# core_model: IP-XACT component
VLNV IcronTechnologies:IcronTechnologies:core_model:1.0

## Parameters
addr_width = 8
bus_width = 32

## Bus interfaces (logical=physical port)
default_map: slave AGNISYS:AGNISYS:APB:1.0, memory map coremap
  pclk=pclk, presetn=presetn, psel=psel, penable=penable, pwrite=pwrite, pprot=pprot, pstrb=pstrb, pwdata=pwdata, paddr=paddr, pready=pready, prdata=prdata, pslverr=pslverr

## Ports
in pclk
in presetn
in psel
in penable
in pwrite
in pprot[2:0]
in pstrb[(bus_width div 8 )-1:0]
in pwdata[bus_width -1:0]
in paddr[addr_width -1:0]
out pready
out prdata[bus_width -1:0]
out pslverr
out mca_core_regscontrol0_enb
out mca_core_regscontrol0_dp_rx_en_r
out mca_core_regscontrol0_dp_tx_en_r
in mca_core_regsstatus0_dp_rx_ready_in
in mca_core_regsstatus0_dp_rx_ready_in_enb
in mca_core_regsstatus0_dp_tx_ready_in
in mca_core_regsstatus0_dp_tx_ready_in_enb
out mca_core_regslink_control0_ltssm_pkt_mngt_pol_enb
out mca_core_regslink_control0_ltssm_pkt_mngt_pol_rx_idl_en_min_r[3:0]
out mca_core_regslink_control0_ltssm_pkt_mngt_pol_tx_idl_min_r[3:0]
out mca_core_regslink_control0_ltssm_pkt_mngt_pol_rx_idl_min_r[3:0]
out mca_core_regslink_control0_ltssm_pkt_mngt_pol_rx_ts1_en_min_r[3:0]
out mca_core_regslink_control0_ltssm_pkt_mngt_pol_tx_ts1_min_r[3:0]
out mca_core_regslink_control0_ltssm_pkt_mngt_pol_rx_ts1_min_r[3:0]
out mca_core_regslink_control0_ltssm_pkt_mngt_rec_enb
out mca_core_regslink_control0_ltssm_pkt_mngt_rec_rx_idl_en_max_lmt_r[3:0]
out mca_core_regslink_control0_ltssm_pkt_mngt_rec_tx_idl_max_lmt_r[3:0]
out mca_core_regslink_control0_ltssm_pkt_mngt_rec_rx_idl_max_lmt_r[3:0]
out mca_core_regslink_control0_ltssm_pkt_mngt_rec_rx_ts2_en_max_lmt_r[3:0]
out mca_core_regslink_control0_ltssm_pkt_mngt_rec_tx_ts2_max_lmt_r[3:0]
out mca_core_regslink_control0_ltssm_pkt_mngt_rec_rx_ts2_max_lmt_r[3:0]
out mca_core_regslink_control0_ltssm_pol_tmr_act_rpt_enb
out mca_core_regslink_control0_ltssm_pol_tmr_act_rpt_lmt_r[31:0]
out mca_core_regslink_control0_ltssm_pol_tmr_idle_rpt_enb
out mca_core_regslink_control0_ltssm_pol_tmr_idle_rpt_lmt_r[31:0]
out mca_core_regslink_control0_ltssm_pol_tmr_idle_enb
out mca_core_regslink_control0_ltssm_pol_tmr_idle_lmt_r[31:0]
out mca_core_regslink_control0_ltssm_rec_tmr_act_rpt_enb
out mca_core_regslink_control0_ltssm_rec_tmr_act_rpt_lmt_r[31:0]
out mca_core_regslink_control0_ltssm_rec_tmr_idle_rpt_enb
out mca_core_regslink_control0_ltssm_rec_tmr_idle_rpt_lmt_r[31:0]
out mca_core_regslink_control0_ltssm_rec_tmr_idle_enb
out mca_core_regslink_control0_ltssm_rec_tmr_idle_lmt_r[31:0]
out mca_core_regslink_control0_ltssm_u0_tmr_u0ltimeout_enb
out mca_core_regslink_control0_ltssm_u0_tmr_u0ltimeout_lmt_r[31:0]
out mca_core_regslink_control0_ltssm_u0_tmr_pnd_enb
out mca_core_regslink_control0_ltssm_u0_tmr_pnd_lmt_r[31:0]
out mca_core_regslink_control0_ltssm_u0_tmr_crd_enb
out mca_core_regslink_control0_ltssm_u0_tmr_crd_lmt_r[31:0]
out mca_core_regslink_control0_ltssm_u0_tmr_u0rectimeout_enb
out mca_core_regslink_control0_ltssm_u0_tmr_u0rectimeout_lmt_r[31:0]
out mca_core_regslink_control0_test_latency_enb
out mca_core_regslink_control0_test_latency_lmt_r[31:0]
out mca_core_regstx_control0_dp_enb
out mca_core_regstx_control0_dp_stats_chid_en_r[15:0]
out mca_core_regstx_control0_dp_bw_pkt_type_r[3:0]
out mca_core_regstx_control0_bw_sample_timer_enb
out mca_core_regstx_control0_bw_sample_timer_cnt_r[15:0]
out mca_core_regstx_stats0_rd2clr_config_rd_valid_out
out mca_core_regstx_stats0_rd2clr_config_wr_valid_out
out mca_core_regstx_stats0_pfifo_rd_valid_out
out mca_core_regstx_stats0_nfifo_rd_valid_out
out mca_core_regstx_stats0_cmd_fifo_dcount_rd_valid_out
out mca_core_regstx_stats0_data_pkt_nrtry_rd_valid_out
out mca_core_regstx_stats0_data_pkt_rtry_rd_valid_out
out mca_core_regstx_stats0_idle_rd_valid_out
out mca_core_regstx_stats0_ts2_rd_valid_out
out mca_core_regstx_stats0_ts1_rd_valid_out
out mca_core_regstx_stats0_lbad_rd_valid_out
out mca_core_regstx_stats0_lrtry_rd_valid_out
out mca_core_regstx_stats0_lcrd_rd_valid_out
out mca_core_regstx_stats0_lgood_rd_valid_out
out mca_core_regstx_stats0_plu_rd_valid_out
out mca_core_regstx_stats0_bandwidth_rd_valid_out
out mca_core_regsrx_control0_dp_enb
out mca_core_regsrx_control0_dp_stats_chid_en_r[15:0]
out mca_core_regsrx_control0_rx_cmd_fifo_flc_enb
out mca_core_regsrx_control0_rx_cmd_fifo_flc_hi_r[15:0]
out mca_core_regsrx_control0_rx_cmd_fifo_flc_lo_r[15:0]
out mca_core_regsrx_stats0_rd2clr_config_rd_valid_out
out mca_core_regsrx_stats0_rd2clr_config_wr_valid_out
out mca_core_regsrx_stats0_cmd_fifo_dcount_rd_valid_out
out mca_core_regsrx_stats0_data_pkt_nrtry_rd_valid_out
out mca_core_regsrx_stats0_data_pkt_rtry_rd_valid_out
out mca_core_regsrx_stats0_idle_rd_valid_out
out mca_core_regsrx_stats0_ts2_rd_valid_out
out mca_core_regsrx_stats0_ts1_rd_valid_out
out mca_core_regsrx_stats0_lbad_rd_valid_out
out mca_core_regsrx_stats0_lrtry_rd_valid_out
out mca_core_regsrx_stats0_lcrd_rd_valid_out
out mca_core_regsrx_stats0_lgood_rd_valid_out
out mca_core_regsrx_stats0_plu_rd_valid_out
out mca_core_regsrx_stats0_rx_cmd_fifo_flc_rd_valid_out

## Address spaces and blocks
coremap.core: base 0x000, range 0x100, width 32

## Registers
Registers are 32-bit, read-only, reset 0x0 unless marked. A register's access mark holds for its fields unless they carry their own. Offsets are from the block's base; lines under a group give offsets from that group; [hi:lo] are bit positions; {n}, {i} and the like mark numbered series; 'fields as' and 'values as' point back to an identical list; <NAME> marks a mode.

## coremap.core — MCA Channel register control
Base 0x00000000
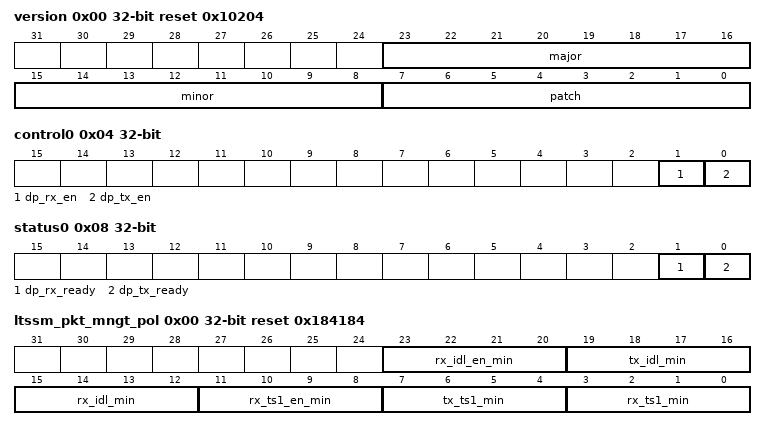
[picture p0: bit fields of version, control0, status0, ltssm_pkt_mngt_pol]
0x00 version reset 0x10204
  [23:16] major — Major version
  [15:8] minor — Minor version
  [7:0] patch — Patch version
0x04 control0 rw
  [1] dp_rx_en — Enables the datapath to receive packets
  [0] dp_tx_en — Enables the datapath to transmit packets
0x08 status0
  [1] dp_rx_ready — Indicates the datapath is ready for transmission
  [0] dp_tx_ready — Indicates the datapath is ready for reception
0x0C link group — This register group contains channel based link management controls and status information.
  0x00 control0 group — This register group contains channel based link management controls and status information.
    0x00 ltssm_pkt_mngt_pol rw reset 0x184184
      [23:20] rx_idl_en_min — Sets the minimum number of idle packets that must be received before starting to count the locally transmitted ts1.
      [19:16] tx_idl_min — Sets the minimum number of idle packets which must be transmitted before moving to the u0 state.
      [15:12] rx_idl_min — Sets minimum number of idle packets which must be received before moving to the u0 state.
      [11:8] rx_ts1_en_min — Sets the minimum number of ts1 packets that must be received before starting to count the locally transmitted ts1.
      [7:4] tx_ts1_min — Sets the minimum number of ts1 packets which must be transmitted before moving to the polling_idle state.
      [3:0] rx_ts1_min — Sets minimum number of ts1 packets which must be received before moving to the polling_idle state.
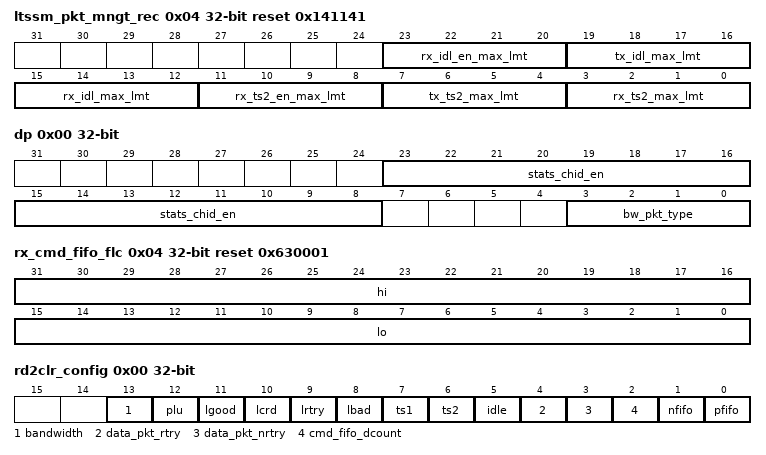
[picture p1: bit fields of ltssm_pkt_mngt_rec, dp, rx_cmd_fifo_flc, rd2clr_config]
    0x04 ltssm_pkt_mngt_rec rw reset 0x141141
      [23:20] rx_idl_en_max_lmt — Sets the minimum number of idle packets that must be received before starting to count the locally transmitted ts2.
      [19:16] tx_idl_max_lmt — Sets the minimum number of idle packets which must be transmitted before moving to the u0 state.
      [15:12] rx_idl_max_lmt — Sets minimum number of idle packets which must be received before moving to the u0 state.
      [11:8] rx_ts2_en_max_lmt — Sets the minimum number of ts2 packets that must be received before starting to count the locally transmitted ts1.
      [7:4] tx_ts2_max_lmt — Sets the minimum number of ts2 packets which must be transmitted before moving to the rec_idle state.
      [3:0] rx_ts2_max_lmt — Sets minimum number of ts2 packets which must be received before moving to the rec_idle state.
    0x08 ltssm_pol_tmr group
      0x00 act_rpt rw reset 0x1D5
        [31:0] lmt — This timer determine the rate at which ts1 packets are transmitted during polling_active (default approximately 3us)
      0x04 idle_rpt rw reset 0x1D5
        [31:0] lmt — This timer determine the rate at which idle packets are transmitted during polling_idle (default approximately 3us)
      0x08 idle rw reset 0x2625A
        [31:0] lmt — When in polling_ilde this timer determine how long to wait before re-starting the polling_active state. (default approximately 1ms)
    0x14 ltssm_rec_tmr group
      0x00 act_rpt rw reset 0x28
        [31:0] lmt — This timer determine the rate at which ts2 packets are transmitted during rec_active. (default approximately 0.25us)
      0x04 idle_rpt rw reset 0x28
        [31:0] lmt — This timer determine the rate at which idle packets are transmitted during rec_idle (default approximately 0.25us)
      0x08 idle rw reset 0x2625A
        [31:0] lmt — When in rec_ilde this timer determine how long to wait before declaring a recovery failure and declaring the port in-active. (default approximately 1ms)
    0x20 ltssm_u0_tmr group
      0x00 u0ltimeout rw reset 0x61B
        [31:0] lmt — When operating in U0 this timer defines the rate at which the system transmits keep alive packets (note these are only done in absence of transmitting data). (default approximately 10us)
      0x04 pnd rw reset 0x3D09
        [31:0] lmt — This timer sets the maximum time limit to wait for a response to be received from the remote port to a retry-able MCUP (default approximately 100us)
      0x08 crd rw reset 0x3D09
        [31:0] lmt — This sets the credit timeout.not implemented yet. (default approximately 100us)
      0x0C u0rectimeout rw reset 0x1312D
        [31:0] lmt — This timer sets the limit on how long to wait without seeing received traffic (link ups/data etc) from the remote end. (default approximately 500us)
    0x30 test group
      0x00 latency rw reset 0x3D09
        [31:0] lmt — This timer sets the rate at which the latency packet sequence is transmitted. Results are stored in the channel associated with the test. (default approximately 100us)
  0x34 status0 group
    0x00 cfg — General configuration settings for the link management logic
      [4:0] active_channels — Indicates how many channels are used in this instance of the MCA.
0x44 tx group
  0x00 control0 group
    0x00 dp rw
      [23:8] stats_chid_en — This field is represents the bit vector which selects the channel(s) which participate in the statistics collection. Bit X 1 - Include channel in statistics collection 0 - Exclude channel from statistics collection
      [3:0] bw_pkt_type — Defines the packet types which bandwidth measurements are taken measured at the egress of the MCA. 0 - all packet types 1 - lgood 2 - lcrd 3 - retriable mcup 4 - non-retriable mcup
    0x04 bw_sample_timer rw reset 0xFF — This register defines the sample period all bandwidth monitors use to calculate the average bandwidth. The clock reference is the core clock.
      [15:0] cnt — Defines the periodicity of the bandwidth sample clock
  0x08 stats0 group
    0x00 rd2clr_config rw — Configures if the stats register read by s/w clears the read register. A 1 in any bit configures the h/w to clear the corresponding stats register after a s/w read of that stats register.
      [13] bandwidth, [12] plu, [11] lgood, [10] lcrd, [9] lrtry, [8] lbad, [7] ts1, [6] ts2, [5] idle, [4] data_pkt_rtry, [3] data_pkt_nrtry, [2] cmd_fifo_dcount, [1] nfifo, [0] pfifo
    0x04 pfifo — Packet FIFO level. This is fixed at 16 elements (16 * 8= 128 bytes)
      [3:0] cnt
    0x08 nfifo — Notification FIFO level. This represents the number of MCUPS in the egress FIFO
      [3:0] cnt
    0x0C cmd_fifo_dcount — This is the common TX Command FIFO level.All channels send link commands through this FIFO
      [15:0] cnt
    0x10 data_pkt_nrtry — This represents the number of non-retriable data-packets are being sent
      [31:0] cnt
    0x14 data_pkt_rtry — This is the number of retriable packets which have been transmitted
      [31:0] cnt
    0x18 idle — Number if idle packets transmitted. These should be relatively low so this counter is small.
      [7:0] cnt
    0x1C ts2 — Number if ts2 packets transmitted. These should be relatively low so this counter is small.
      [7:0] cnt
    0x20 ts1 — Number if ts1 packets transmitted. These should be relatively low so this counter is small.
      [7:0] cnt
    0x24 lbad — Number of LBAD packets transmitted.
      [7:0] cnt
    0x28 lrtry — Number of retry requests sent to the remote end
      [7:0] cnt
    0x2C lcrd — Number of credit packets transmitted.
      [7:0] cnt
    0x30 lgood — Number of LGOOD packets transmitted.
      [31:0] cnt
    0x34 plu — Number of keep alive packets transmitted
      [7:0] cnt
    0x38 bandwidth — This register reports the high level watermark of the egress bandwidth. *NOTE: this depends on the configuration which packets types are measured
      [15:0] cnt
0x88 rx group
  0x00 control0 group
    0x00 dp rw
      [15:0] stats_chid_en — This field is represents the bit vector which selects the channel(s) which participate in the statistics collection. Bit X 1 - Include channel in statistics collection 0 - Exclude channel from statistics collection
    0x04 rx_cmd_fifo_flc rw reset 0x630001 — The RX command flow control sets the hysteresis points which enable or disable flow control globally on the data-path. The RX command FIFO contains all responses generated from the RX link management logic. This is a relatively large FIFO and is designed to hold more data than the TX channel FIFO's. Commands in this FIFO are critical and must not be lost. When the FIFO reaches its upper limit it will prevent transmission of data payloads over the link allowing a bias to the TX command FIFO's to drain, and henceforth allowing the RX command FIFO to drain.
      [31:16] hi — When the FIFO reaches this limit the system will enter flow control.
      [15:0] lo — When the FIFO threshold reaches this threshold flow control will be disabled and normal operation can occur.
  0x08 stats0 group — All the Statistic Registers and their configuration for the Write Engine
    0x00 rd2clr_config rw — Configures if the stats register read by s/w clears the read register. A 1 in any bit configures the h/w to clear the corresponding stats register after a s/w read of that stats register.
      [11] rx_cmd_fifo_flc, [10] plu, [9] lgood, [8] lcrd, [7] lrtry, [6] lbad, [5] ts1, [4] ts2, [3] idle, [2] data_pkt_rtry, [1] data_pkt_nrtry, [0] cmd_fifo_dcount
    0x04 cmd_fifo_dcount — This is the common RX Command FIFO level.All channels receive link commands through this FIFO
      [15:0] cnt
    0x08 data_pkt_nrtry — This represents the number of non-retriable data-packets received
      [31:0] cnt
    0x0C data_pkt_rtry — This is the number of retriable packets which have been received
      [31:0] cnt
    0x10 idle — Number of idle packets received. These should be relatively low so this counter is small.
      [7:0] cnt
    0x14 ts2 — Number of ts2 packets received. These should be relatively low so this counter is small.
      [7:0] cnt
    0x18 ts1 — Number of ts1 packets received. These should be relatively low so this counter is small.
      [7:0] cnt
    0x1C lbad — Number of LBAD packets received.
      [7:0] cnt
    0x20 lrtry — Number of retry requests sent to the remote end
      [7:0] cnt
    0x24 lcrd — Number of credit packets received.
      [7:0] cnt
    0x28 lgood — Number of LGOOD packets transmitted.
      [31:0] cnt
    0x2C plu — Number of keep alive packets received
      [7:0] cnt
    0x30 rx_cmd_fifo_flc — Counts the number of clock cycles the RX command FIFO flow control state has been active
      [7:0] cnt
0xC4 irq0 group — MCA channel interrupts
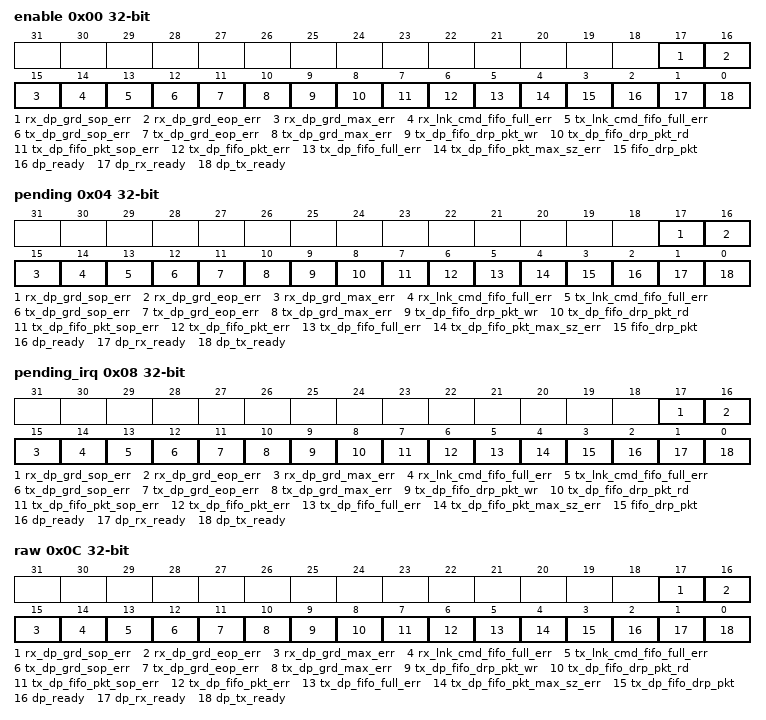
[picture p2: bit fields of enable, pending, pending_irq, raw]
  0x00 enable rw — Interrupt Enable register - Write 1 to enable, 0 to mask an interrupt
    [17] rx_dp_grd_sop_err, [16] rx_dp_grd_eop_err, [15] rx_dp_grd_max_err, [14] rx_lnk_cmd_fifo_full_err, [13] tx_lnk_cmd_fifo_full_err, [12] tx_dp_grd_sop_err, [11] tx_dp_grd_eop_err, [10] tx_dp_grd_max_err, [9] tx_dp_fifo_drp_pkt_wr, [8] tx_dp_fifo_drp_pkt_rd, [7] tx_dp_fifo_pkt_sop_err, [6] tx_dp_fifo_pkt_err, [5] tx_dp_fifo_full_err, [4] tx_dp_fifo_pkt_max_sz_err, [3] fifo_drp_pkt, [2] dp_ready, [1] dp_rx_ready, [0] dp_tx_ready
  0x04 pending rw — Interrupt Pending register - This indicates which enabled interrupts have triggered, Write 1 to clear
    [17] rx_dp_grd_sop_err write-1-clears, [16] rx_dp_grd_eop_err write-1-clears, [15] rx_dp_grd_max_err write-1-clears, [14] rx_lnk_cmd_fifo_full_err write-1-clears, [13] tx_lnk_cmd_fifo_full_err write-1-clears, [12] tx_dp_grd_sop_err write-1-clears, [11] tx_dp_grd_eop_err write-1-clears, [10] tx_dp_grd_max_err write-1-clears, [9] tx_dp_fifo_drp_pkt_wr write-1-clears, [8] tx_dp_fifo_drp_pkt_rd write-1-clears, [7] tx_dp_fifo_pkt_sop_err write-1-clears, [6] tx_dp_fifo_pkt_err write-1-clears, [5] tx_dp_fifo_full_err write-1-clears, [4] tx_dp_fifo_pkt_max_sz_err write-1-clears, [3] fifo_drp_pkt write-1-clears, [2] dp_ready write-1-clears, [1] dp_rx_ready write-1-clears, [0] dp_tx_ready write-1-clears
  0x08 pending_irq — Interrupt Pending register - This indicates which enabled interrupts have been triggered, Write 1 to clear
    fields as irq0.enable
  0x0C raw — This register contains the active state of interrupt sources
    [17] rx_dp_grd_sop_err — Pulse. Critical Error
    [16] rx_dp_grd_eop_err — Pulse. Critical Error
    [15] rx_dp_grd_max_err — Pulse. Critical Error
    [14] rx_lnk_cmd_fifo_full_err — (Active High)-rising edge-Critical Error
    [13] tx_lnk_cmd_fifo_full_err — (Active High)-rising edge-Critical Error
    [12] tx_dp_grd_sop_err — Pulse. Critical Error
    [11] tx_dp_grd_eop_err — Pulse. Critical Error
    [10] tx_dp_grd_max_err — Pulse. Critical Error
    [9] tx_dp_fifo_drp_pkt_wr — Pulse. Critical Error
    [8] tx_dp_fifo_drp_pkt_rd — Pulse. Critical Error
    [7] tx_dp_fifo_pkt_sop_err — Pulse. Critical Error
    [6] tx_dp_fifo_pkt_err — (Active High)-rising edge-Critical Error
    [5] tx_dp_fifo_full_err — (Active High)-rising edge-Critical Error
    [4] tx_dp_fifo_pkt_max_sz_err — Pulse. Critical Error
    [3] tx_dp_fifo_drp_pkt — Pulse. Critical Error
    [2] dp_ready — (Active-High), rising and falling edge
    [1] dp_rx_ready — (Active-High), rising and falling edge
    [0] dp_tx_ready — (Active-High), rising and falling edge
